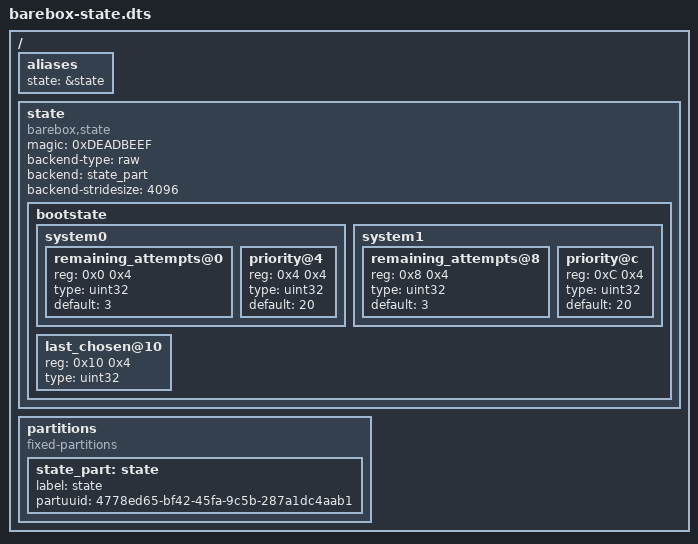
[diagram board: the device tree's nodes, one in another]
/dts-v1/;
/ {
    aliases {
        state = &state;
    };

    state: state {
        magic = <0xDEADBEEF>;
        compatible = "barebox,state";
        backend-type = "raw";
        backend = <&state_part>;
        backend-stridesize = <4096>; /* partition must be at least 3x this*/
    
        /* initial variables */
        bootstate {
                #address-cells = <1>;
                #size-cells = <1>;

                system0 { /* the node's name here must match the subnode's name in the 'bootstate' node */
                        #address-cells = <1>;
                        #size-cells = <1>;

                        remaining_attempts@0 {
                                reg = <0x0 0x4>;
                                type = "uint32";
                                default = <3>;
                        };
                        priority@4 {
                                reg = <0x4 0x4>;
                                type = "uint32";
                                default = <20>;
                        };
                };

                system1 { /* the node's name here must match the subnode's name in the 'bootstate' node */
                        #address-cells = <1>;
                        #size-cells = <1>;

                        remaining_attempts@8 {
                                reg = <0x8 0x4>;
                                type = "uint32";
                                default = <3>;
                        };
                        priority@c {
                                reg = <0xC 0x4>;
                                type = "uint32";
                                default = <20>;
                        };
                };

                last_chosen@10 {
                        reg = <0x10 0x4>;
                        type = "uint32";
                 };
         };
    };

    partitions {
        compatible = "fixed-partitions";

        state_part: state {
            label = "state";
            partuuid = "4778ed65-bf42-45fa-9c5b-287a1dc4aab1";
        };
    };
};
